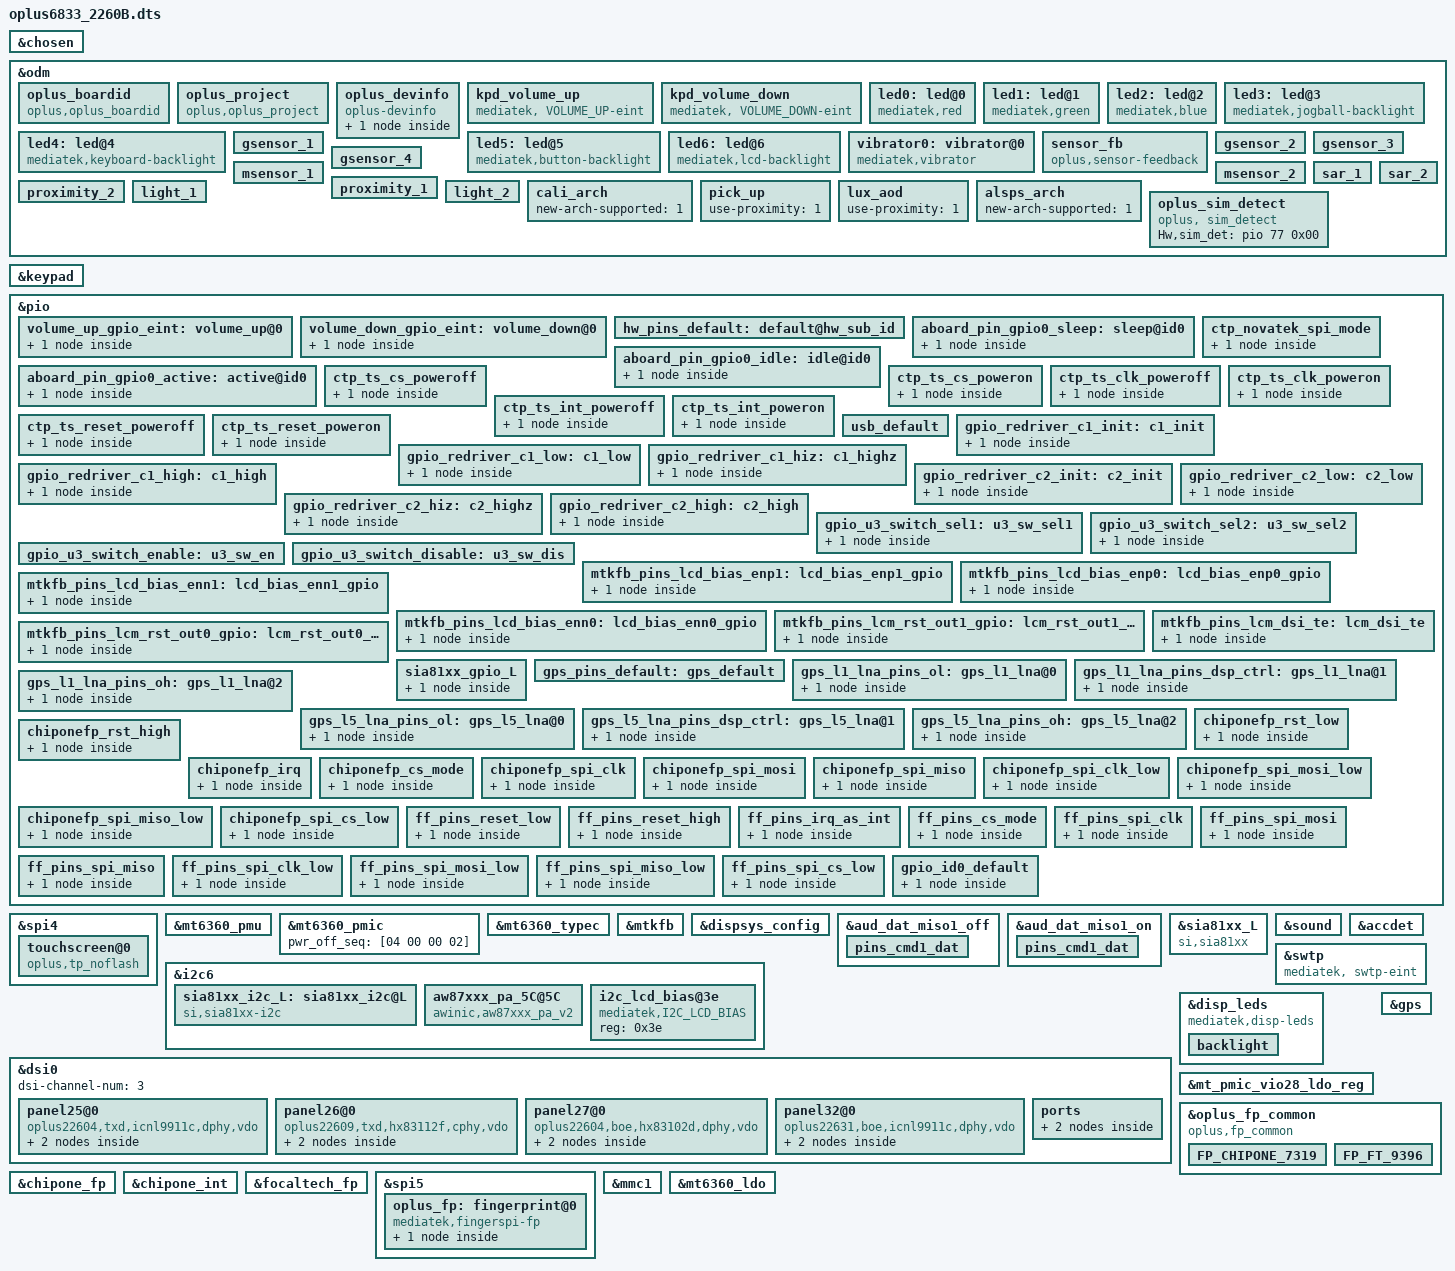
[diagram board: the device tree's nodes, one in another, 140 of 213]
// SPDX-License-Identifier: GPL-2.0
/*
 * Copyright (c) 2019 MediaTek Inc.
 *
 */
/dts-v1/;
/plugin/;
#include <dt-bindings/interrupt-controller/irq.h>
#include <dt-bindings/interrupt-controller/arm-gic.h>
#ifndef CONFIG_FPGA_EARLY_PORTING
#include <dt-bindings/pinctrl/mt6833-pinfunc.h>
#endif

/* chosen */
&chosen {
	atag,videolfb-fb_base_l = <0x7e605000>;
	atag,videolfb-fb_base_h = <0x0>;
	atag,videolfb-islcmfound = <1>;
	atag,videolfb-islcm_inited = <0>;
	atag,videolfb-fps= <6000>;
	atag,videolfb-vramSize= <0x1be0000>;
	atag,videolfb-lcmname=
		"nt35595_fhd_dsi_cmd_truly_nt50358_drv";
};

&odm {
	oplus_boardid:oplus_boardid {
		compatible = "oplus,oplus_boardid";
		oplus_boardid,dtsino="0x2260B";//only one u32
		oplus_boardid,pcbmask="0xffff";//all mask 0xffff
	};
	oplus_project:oplus_project {
		compatible = "oplus,oplus_project";
	};

	oplus_devinfo:oplus_devinfo {
		compatible = "oplus-devinfo";
		pinctrl-names = "default", "aboard_gpio0_sleep", "aboard_gpio0_active", "aboard_gpio0_idle";
		pinctrl-0 = <&hw_pins_default>;
		pinctrl-1 = <&aboard_pin_gpio0_sleep>;
		pinctrl-2 = <&aboard_pin_gpio0_active>;
		pinctrl-3 = <&aboard_pin_gpio0_idle>;
		main-sub {
			use_tristate_gpio;
			compatible = "hw-match, main-sub";
			aboard-gpio0 = <&pio 91 0x00>;
			aboard-patterns = <1>;	/*0[high-resistance] 1[pull-down] 2[pull-up]*/
			/*main board*/
			match-projects = <0x2260B>;
		};
	};

	kpd_volume_up:kpd_volume_up {
		compatible = "mediatek, VOLUME_UP-eint";
		interrupt-parent = <&pio>;
		interrupts = <1 IRQ_TYPE_EDGE_FALLING 1 0>;
		debounce = <32000>;
		status = "okay";
	};

	kpd_volume_down:kpd_volume_down {
		compatible = "mediatek, VOLUME_DOWN-eint";
		interrupt-parent = <&pio>;
		interrupts = <80 IRQ_TYPE_EDGE_FALLING 80 0>;
		debounce = <32000>;
		status = "okay";
	};
};
&keypad {
	keypad,volume-up	= <&pio 1 0x00>;
	keypad,volume-down	= <&pio 80 0x00>;
	pinctrl-names = "volume_up_as_int", "volume_down_as_int";
	pinctrl-0 = <&volume_up_gpio_eint>;
	pinctrl-1 = <&volume_down_gpio_eint>;
	status = "okay";
};
&pio {
	volume_up_gpio_eint:volume_up@0{
		pins_cmd_dat {
			pinmux = <PINMUX_GPIO1__FUNC_GPIO1>;
			slew-rate = <0>;  /*direction 0:in, 1:out*/
			input-enable;
		};
	};

	volume_down_gpio_eint:volume_down@0{
		pins_cmd_dat {
			pinmux = <PINMUX_GPIO80__FUNC_GPIO80>;
			slew-rate = <0>;  /*direction 0:in, 1:out*/
			input-enable;
		};
	};

	hw_pins_default:default@hw_sub_id {
	};
	aboard_pin_gpio0_sleep:sleep@id0 {
		pins_cmd_dat {
			pinmux = <PINMUX_GPIO91__FUNC_GPIO91>;
			slew-rate = <0>;
			bias-pull-down;
			input-enable;
		};
	};

	aboard_pin_gpio0_active:active@id0 {
		pins_cmd_dat {
			pinmux = <PINMUX_GPIO91__FUNC_GPIO91>;
			slew-rate = <0>;
			bias-pull-up;
			input-enable;
		};
	};

	aboard_pin_gpio0_idle:idle@id0 {
		pins_cmd_dat {
			pinmux = <PINMUX_GPIO91__FUNC_GPIO91>;
			slew-rate = <0>;
			bias-disable;
			input-enable;
		};
	};
};

&spi4 {
	status = "okay";
	#address-cells = <1>;
	#size-cells = <0>;

	touchscreen@0 {
		compatible = "oplus,tp_noflash";
		reg = <0>;
		chip-name = "himax,hx83112f_nf";
		status = "okay";

		spi-max-frequency = <9600000>;	//4800000,9600000,15000000,19200000
		interrupt-parent = <&pio>;
		interrupts = <14 IRQ_TYPE_EDGE_FALLING 14 0>;
		irq-gpio = <&pio 14 0x2002>;
		reset-gpio = <&pio 15 0>;

		/*driver match info*/
		tp_type = <21>; /*type:21 txd*/
		firmware_name = "0xAA270BI01";
		platform_support_project = <22609 22669 0x2260B 0x2266A 0x2266B 0x2266C>;
		platform_support_project_dir = <22609 22669 0x2260B 0x2266A 0x2266B 0x2266C>;
		platform_support_project_commandline = "default_commandline", "default_commandline", "default_commandline", "default_commandline", "default_commandline", "default_commandline";

		/*panel properities*/
		touchpanel,max-num-support = <10>;
		touchpanel,tx-rx-num = <16 36>;
		touchpanel,panel-coords = <1080 2408>;
		touchpanel,display-coords = <1080 2408>;
		touchpanel,touchmajor-limit = <0 216>;

		/*tp-pinctrl*/
		pinctrl-names = "default", "pin_set_low", "pin_set_high";
		pinctrl-0 = <&ctp_ts_int_poweron &ctp_ts_reset_poweron &ctp_novatek_spi_mode>;
		pinctrl-1 = <&ctp_ts_int_poweroff &ctp_ts_reset_poweroff &ctp_ts_cs_poweroff &ctp_ts_clk_poweroff>;
		pinctrl-2 = <&ctp_ts_int_poweron &ctp_ts_reset_poweron &ctp_ts_cs_poweron &ctp_ts_clk_poweron>;

		/*sw-feature*/
		incell_screen;
		irq_need_dev_resume_ok;
		fw_edge_limit_support;
		black_gesture_support;
		charger_pump_support;
		headset_pump_support;
		esd_handle_support;
		black_gesture_test_support;
		game_switch_support;
		noflash_support;
		lcd_trigger_load_tp_fw_support;
		smart_gesture_support;
		pressure_report_support;
		fw_update_app_support;
		health_monitor_v2_support;
		fw_update_in_probe_with_headfile;

		touchpanel,button-type = <4>;
	};

};

&pio {
	ctp_novatek_spi_mode:ctp_novatek_spi_mode{
		pins_cmd_dat {
			pinmux = <PINMUX_GPIO12__FUNC_SPI4_MI>,
				<PINMUX_GPIO13__FUNC_SPI4_MO>,
				<PINMUX_GPIO97__FUNC_SPI4_CLK>,
				<PINMUX_GPIO98__FUNC_SPI4_CSB>;
			drive-strength = <4>;
		};
	};
	ctp_ts_cs_poweroff: ctp_ts_cs_poweroff {
		pins_cmd_dat {
			pinmux = <PINMUX_GPIO98__FUNC_GPIO98>;
			slew-rate = <1>;
			output-low;
			bias-disable;
			//drive-strength = <4>;
		};
	};
	ctp_ts_cs_poweron: ctp_ts_cs_poweron {
		pins_cmd_dat {
			pinmux = <PINMUX_GPIO98__FUNC_SPI4_CSB>;
			drive-strength = <4>;
			//output-high;
		};
	};
	ctp_ts_clk_poweroff: ctp_ts_clk_poweroff {
		pins_cmd_dat {
			pinmux = <PINMUX_GPIO97__FUNC_GPIO97>;
			slew-rate = <1>;
			output-low;
			bias-disable;
			//drive-strength = <4>;
		};
	};
	ctp_ts_clk_poweron: ctp_ts_clk_poweron {
		pins_cmd_dat {
			pinmux = <PINMUX_GPIO97__FUNC_SPI4_CLK>;
			drive-strength = <4>;
			//output-high;
		};
	};
	ctp_ts_int_poweroff: ctp_ts_int_poweroff {
		pins_cmd_dat {
			pinmux = <PINMUX_GPIO14__FUNC_GPIO14>;
			slew-rate = <1>;
			output-low;
			bias-disable;
		};
	};
	ctp_ts_int_poweron: ctp_ts_int_poweron {
		pins_cmd_dat {
			pinmux = <PINMUX_GPIO14__FUNC_GPIO14>;
			slew-rate = <0>;
			input-enable;
			bias-pull-up = <00>;
		};
	};
	ctp_ts_reset_poweroff: ctp_ts_reset_poweroff {
		pins_cmd_dat {
			pinmux = <PINMUX_GPIO15__FUNC_GPIO15>;
			slew-rate = <1>;
			output-low;
			bias-disable;
		};
	};

	ctp_ts_reset_poweron: ctp_ts_reset_poweron {
		pins_cmd_dat {
			pinmux = <PINMUX_GPIO15__FUNC_GPIO15>;
			slew-rate = <1>;
			output-high;
			bias-disable;
		};
	};
};

/* USB SWITCH GPIO start */
&pio {
	usb_default: usb_default {
	};

	gpio_redriver_c1_init: c1_init {
		pins_cmd_dat {
			pinmux = <PINMUX_GPIO41__FUNC_GPIO41>;
			slew-rate = <1>;
			output-low;
		};
	};

	gpio_redriver_c1_low: c1_low {
		pins_cmd_dat {
			pinmux = <PINMUX_GPIO41__FUNC_GPIO41>;
			slew-rate = <1>;
			output-low;
		};
	};

	gpio_redriver_c1_hiz: c1_highz {
		pins_cmd_dat {
			pinmux = <PINMUX_GPIO41__FUNC_GPIO41>;
			slew-rate= <0>;
			bias-disable;
		};
	};

	gpio_redriver_c1_high: c1_high {
		pins_cmd_dat {
			pinmux = <PINMUX_GPIO41__FUNC_GPIO41>;
			slew-rate = <1>;
			output-high;
		};
	};

	gpio_redriver_c2_init: c2_init {
		pins_cmd_dat {
			pinmux = <PINMUX_GPIO40__FUNC_GPIO40>;
			slew-rate = <1>;
			output-low;
		};
	};

	gpio_redriver_c2_low: c2_low {
		pins_cmd_dat {
			pinmux = <PINMUX_GPIO40__FUNC_GPIO40>;
			slew-rate = <1>;
			output-low;
		};
	};

	gpio_redriver_c2_hiz: c2_highz {
		pins_cmd_dat {
			pinmux = <PINMUX_GPIO40__FUNC_GPIO40>;
			slew-rate= <0>;
			bias-disable;
		};
	};

	gpio_redriver_c2_high: c2_high {
		pins_cmd_dat {
			pinmux = <PINMUX_GPIO40__FUNC_GPIO40>;
			slew-rate = <1>;
			output-high;
		};
	};

	gpio_u3_switch_sel1: u3_sw_sel1 {
		pins_cmd_dat {
			pinmux = <PINMUX_GPIO11__FUNC_GPIO11>;
			slew-rate = <1>;
			output-low;
		};
	};

	gpio_u3_switch_sel2: u3_sw_sel2 {
		pins_cmd_dat {
			pinmux = <PINMUX_GPIO11__FUNC_GPIO11>;
			slew-rate = <1>;
			output-high;
		};
	};

	gpio_u3_switch_enable: u3_sw_en {
	};

	gpio_u3_switch_disable: u3_sw_dis {
	};
};

&mt6360_pmu {
	mt6360,intr_gpio_num = <10>; /* direct defined GPIO num */
	mt6360,intr_gpio = <&pio 10 0x0>;
};

&mt6360_pmic {
	pwr_off_seq = [04 00 00 02];
};

&mt6360_typec {
	mt6360pd,intr_gpio_num = <11>; /* direct defined GPIO num */
	mt6360pd,intr_gpio = <&pio 11 0x0>;
};

#ifndef CONFIG_FPGA_EARLY_PORTING
&pio {
	mtkfb_pins_lcd_bias_enp1: lcd_bias_enp1_gpio {
		pins_cmd_dat {
			pinmux = <PINMUX_GPIO137__FUNC_GPIO137>;
			slew-rate = <1>;
			output-high;
		};
	};

	mtkfb_pins_lcd_bias_enp0: lcd_bias_enp0_gpio {
		pins_cmd_dat {
			pinmux = <PINMUX_GPIO137__FUNC_GPIO137>;
			slew-rate = <1>;
			output-low;
		};
	};

	mtkfb_pins_lcd_bias_enn1: lcd_bias_enn1_gpio {
		pins_cmd_dat {
			pinmux = <PINMUX_GPIO138__FUNC_GPIO138>;
			slew-rate = <1>;
			output-high;
		};
	};

	mtkfb_pins_lcd_bias_enn0: lcd_bias_enn0_gpio {
		pins_cmd_dat {
			pinmux = <PINMUX_GPIO138__FUNC_GPIO138>;
			slew-rate = <1>;
			output-low;
		};
	};

	mtkfb_pins_lcm_rst_out1_gpio: lcm_rst_out1_gpio {
		pins_cmd_dat {
			pinmux = <PINMUX_GPIO86__FUNC_GPIO86>;
			slew-rate = <1>;
			output-high;
		};
	};

	mtkfb_pins_lcm_rst_out0_gpio: lcm_rst_out0_gpio {
		pins_cmd_dat {
			pinmux = <PINMUX_GPIO86__FUNC_GPIO86>;
			slew-rate = <1>;
			output-low;
		};
	};
	mtkfb_pins_lcm_dsi_te: lcm_dsi_te {
		pins_cmd_dat {
			pinmux = <PINMUX_GPIO84__FUNC_DSI_TE>;
		};
	};
};

&mtkfb {
	pinctrl-names = "lcd_bias_enp1_gpio", "lcd_bias_enp0_gpio",
		"lcd_bias_enn1_gpio", "lcd_bias_enn0_gpio",
		"lcm_rst_out1_gpio", "lcm_rst_out0_gpio",
		"mode_te_te";
	pinctrl-0 = <&mtkfb_pins_lcd_bias_enp1>;
	pinctrl-1 = <&mtkfb_pins_lcd_bias_enp0>;
	pinctrl-2 = <&mtkfb_pins_lcd_bias_enn1>;
	pinctrl-3 = <&mtkfb_pins_lcd_bias_enn0>;
	pinctrl-4 = <&mtkfb_pins_lcm_rst_out1_gpio>;
	pinctrl-5 = <&mtkfb_pins_lcm_rst_out0_gpio>;
	pinctrl-6 = <&mtkfb_pins_lcm_dsi_te>;
	status = "okay";
};
&dispsys_config {
	pinctrl-names =
		"lcm_rst_out1_gpio", "lcm_rst_out0_gpio",
		"mode_te_te";
	pinctrl-0 = <&mtkfb_pins_lcm_rst_out1_gpio>;
	pinctrl-1 = <&mtkfb_pins_lcm_rst_out0_gpio>;
	pinctrl-2 = <&mtkfb_pins_lcm_dsi_te>;
	status = "okay";

	helper-value = <0>, /*MTK_DRM_OPT_STAGE*/
		<1>, /*MTK_DRM_OPT_USE_CMDQ*/
		<1>, /*MTK_DRM_OPT_USE_M4U*/
		<0>, /*MTK_DRM_OPT_SODI_SUPPORT*/
		<1>, /*MTK_DRM_OPT_IDLE_MGR*/
		<0>, /*MTK_DRM_OPT_IDLEMGR_SWTCH_DECOUPLE*/
		<0>, /*MTK_DRM_OPT_IDLEMGR_BY_REPAINT*/
		<0>, /*MTK_DRM_OPT_IDLEMGR_ENTER_ULPS*/
		<0>, /*MTK_DRM_OPT_IDLEMGR_KEEP_LP11*/
		<0>, /*MTK_DRM_OPT_DYNAMIC_RDMA_GOLDEN_SETTING*/
		<1>, /*MTK_DRM_OPT_IDLEMGR_DISABLE_ROUTINE_IRQ*/
		<0>, /*MTK_DRM_OPT_MET_LOG*/
		<1>, /*MTK_DRM_OPT_USE_PQ*/
		<1>, /*MTK_DRM_OPT_ESD_CHECK_RECOVERY*/
		<0>, /*MTK_DRM_OPT_ESD_CHECK_SWITCH*/
		<1>, /*MTK_DRM_OPT_PRESENT_FENCE*/
		<0>, /*MTK_DRM_OPT_RDMA_UNDERFLOW_AEE*/
		<1>, /*MTK_DRM_OPT_DSI_UNDERRUN_AEE*/
		<1>, /*MTK_DRM_OPT_HRT*/
		<1>, /*MTK_DRM_OPT_HRT_MODE*/
		<0>, /*MTK_DRM_OPT_DELAYED_TRIGGER*/
		<1>, /*MTK_DRM_OPT_OVL_EXT_LAYER*/
		<0>, /*MTK_DRM_OPT_AOD*/
		<1>, /*MTK_DRM_OPT_RPO*/
		<0>, /*MTK_DRM_OPT_DUAL_PIPE*/
		<0>, /*MTK_DRM_OPT_DC_BY_HRT*/
		<0>, /*MTK_DRM_OPT_OVL_WCG*/
		<0>, /*MTK_DRM_OPT_OVL_SBCH*/
		<1>, /*MTK_DRM_OPT_COMMIT_NO_WAIT_VBLANK*/
		<0>, /*MTK_DRM_OPT_MET*/
		<0>, /*MTK_DRM_OPT_REG_PARSER_RAW_DUMP*/
		<0>, /*MTK_DRM_OPT_VP_PQ*/
		<0>, /*MTK_DRM_OPT_GAME_PQ*/
		<0>, /*MTK_DRM_OPT_MMPATH*/
		<0>, /*MTK_DRM_OPT_HBM*/
		<1>, /*MTK_DRM_OPT_VDS_PATH_SWITCH*/
		<0>, /*MTK_DRM_OPT_LAYER_REC*/
		<1>; /*MTK_DRM_OPT_CLEAR_LAYER*/
};

/* add for dual-mic or singlemic with miso1 */
&aud_dat_miso1_off {
	pins_cmd1_dat {
		pinmux = <PINMUX_GPIO160__FUNC_GPIO160>;
		input-enable;
		bias-pull-down;
	};
};
&aud_dat_miso1_on {
	pins_cmd1_dat {
		pinmux = <PINMUX_GPIO160__FUNC_AUD_DAT_MISO1>;
		input-schmitt-enable;
		bias-disable;
	};
};

&pio {
	sia81xx_gpio_L: sia81xx_gpio_L {
		pins_cmd_dat {
			pinmux = <PINMUX_GPIO94__FUNC_GPIO94>;
			slew-rate = <1>;
			bias-disable;
		};
	};
};

&sia81xx_L {
	compatible = "si,sia81xx";
	si,sia81xx_type = "sia8100";
	si,sia81xx_reset = <&pio 94 0>;
	si,sia81xx_owi = <&pio 94 0>;
	si,sia_boost_vol_support = <1>;
	pinctrl-names = "sia81xx_gpio";
	pinctrl-0 = <&sia81xx_gpio_L>;
	si,sia81xx_disable_pin = <0>;
	/* the same value share a same task
	 * valid value range : 0 ~ 7 */
	timer_task_hdl = <0>;
	channel_num = <0>;
	owi_mode = <2>;
	en_x_filter = <0>;
	en_dynamic_updata_vdd = <1>;
	dynamic_updata_vdd_port = <0x8>;
	algo_is_v2 = <1>;
};

&sound {
	/* this dtsi config for product's special config, AudioHal read ctl 'OPLUS_AUDIO_EXTEN_CONFIG' get the values*
	 * 1st value --> PA type: 0:NXP Pa, 1:Awinic Pa 2:sia81xx Pa*/
	audio_extern_config = <2>;
	si,sia81xx-max-num = <1>;
	si,sia81xx-aux-devs = <&sia81xx_L>;
	si,sia81xx-aux-devs-prefix = "SpkrLeft";
};

&i2c6 {
        sia81xx_i2c_L: sia81xx_i2c@L {
                compatible = "si,sia81xx-i2c";
                reg = <0x28>;
                si,sia81xx-dev = <&sia81xx_L>;
        };

	aw87xxx_pa_5C@5C {
		compatible = "awinic,aw87xxx_pa_v2";
		reset-gpio = <&pio 94 0>;
		reg = <0x5C>;
		dev_index = < 0 >;
		status = "okay";
	};

       i2c_lcd_bias@3e {
               compatible = "mediatek,I2C_LCD_BIAS";
               reg = <0x3e>;
               status = "okay";
       };
};

&dsi0 {
	status = "okay";
	dsi-channel-num = <3>;
	#address-cells = <1>;
	#size-cells = <0>;
	panel25@0 {
		compatible = "oplus22604,txd,icnl9911c,dphy,vdo";
		reg = <0>;
		reset-gpios = <&pio 86 0>;
		ldo-gpios = <&pio 41 0>;
		bias-gpios = <&pio 138 0>,
				<&pio 137 0>;
		pinctrl-names = "default";
		port {
			panel_in25: endpoint {
				remote-endpoint = <&dsi_out>;
			};
		};
	};
	panel26@0 {
		compatible = "oplus22609,txd,hx83112f,cphy,vdo";
		reg = <1>;
		reset-gpios = <&pio 86 0>;
		ldo-gpios = <&pio 41 0>;
		bias-gpios = <&pio 138 0>,
				<&pio 137 0>;
		pinctrl-names = "default";
		port {
			panel_in26: endpoint {
				remote-endpoint = <&dsi_out>;
			};
		};
	};
	panel27@0 {
		compatible = "oplus22604,boe,hx83102d,dphy,vdo";
		reg = <2>;
		reset-gpios = <&pio 86 0>;
		ldo-gpios = <&pio 41 0>;
		bias-gpios = <&pio 138 0>,
				<&pio 137 0>;
		pinctrl-names = "default";
		port {
			panel_in27: endpoint {
				remote-endpoint = <&dsi_out>;
			};
		};
	};
	panel32@0 {
		compatible = "oplus22631,boe,icnl9911c,dphy,vdo";
		reg = <3>;
		reset-gpios = <&pio 86 0>;
		ldo-gpios = <&pio 41 0>;
		bias-gpios = <&pio 138 0>,
				<&pio 137 0>;
		pinctrl-names = "default";
		port {
			panel_in32: endpoint {
				remote-endpoint = <&dsi_out>;
			};
		};
	};
	ports {
		port {
			dsi_out: endpoint {
				remote-endpoint = <&panel_in25>;
			};
		};
	};
};
#endif

/* delete default keys pinctrl
&keypad {
	pinctrl-names = "default";
	pinctrl-0 = <&kpd_pins_default>;
};

&pio {
	kpd_pins_default: kpdgpiodefault {
		pins_cmd_dat {
			pinmux = <PINMUX_GPIO79__FUNC_KPCOL0>;
			bias-pull-up = <MTK_PUPD_SET_R1R0_10>;
			output-low;
			input-schmitt-enable;
		};
	};
};
*/

//#include "mediatek/cust_mt6833_touch_1080x2300.dtsi"
/* accdet start */
&accdet {
	/* accdet micbias voltage: 0x09:2.85v 0x08:2.8v 0x07,
	 * 2.7v;0x05,2.5v;0x02,1.9v
	 */
	accdet-mic-vol = <7>;
	/* accdet pwm_width, pwm_thresh, fall_delay, rise_delay
	 * debounce0, debounce1, debounce3, debounce4
	 * eint pwm_width, eint pwm_thresh
	 * eint deb(debounce0, debounce1, debounce2, debounce3), inv_debounce
	 */

	headset-mode-setting = <0x500 0x500 1 0x1f0
				0x1325 0x800 0x3D4 0x44
				0x0 0x7
				0x5 0x9 0x9 0xd 0xe>;
	/*headset-mode-setting = <0x500 0x500 1 0x1f0
	*                      0x800 0x800 0x20 0x44
	*                      0x4 0x1
	*                      0x5 0x3 0x3 0x5 0xe>;
	*/

	accdet-plugout-debounce = <1>;
	/*1:ACC mode, 2:low cost without in bias, 6:low cost with in bias*/
	accdet-mic-mode = <2>;
	/*0--MD_MAX--UP_MAX--DW_MAX*/
	headset-three-key-threshold = <0 82 170 306>;
	//headset-three-key-threshold = <0 80 220 400>;
	headset-three-key-threshold-CDD = <0 121 192 600>;
	/*0--MD_MAX--VOICE_MAX--UP_MAX--DW_MAX*/
	headset-four-key-threshold = <0 58 121 192 400>;
	/* moisture HW mode config start. Enable moisture detection or not
	 * default use HW mode for moisture detection
	 */
	moisture_detect_enable = <1>;
	/* select VTH to 2v and 500k, use internal resitance */
	eint_use_ext_res = <0>;
	/* enable eint detection mode, if moisture detection enable
	 * eint_detect_mode = moisture_detect_mode;otherwise, select
	 * eint_detect_mode = 4 as DEFAULT
	 */
	eint_detect_mode = <5>;
	/* enable moisture detection mode, if moisture detection enable
	 * eint_detect_mode = moisture_detect_mode
	 */
	moisture_detect_mode = <5>;
	/* select 0: 2.8V; 1: 2.4V; 2: 2V; 3: VTH=MVTH(VTH2) */
	moisture_comp_vth = <2>;
//#ifdef OPLUS_BUG_COMPATIBILITY
	moisture_comp_vref2 = <2>;
//#else
	/* vref2 voltage for different water impedance */
	//moisture_comp_vref2 = <0>;
//#endif
	/* moisture HW mode config end */

	/* moisture SW mode config start, use external resister or not.
	 * DEFAULT NOT NEED
	 */
	moisture_use_ext_res = <0>;
	/* moisture external resister ohm, SW mode by auxadc */
	moisture-external-r = <2000000>;
	/* moisture internal resister ohm, SW mode by auxadc */
	moisture-internal-r = <47000>;
	/* moisture of water resister ohm, SW mode by auxadc*/
	moisture-water-r = <10000>;
	/* moisture SW mode config end */
        //#endif /* VENDOR_EDIT */
	status = "okay";
};
/* accdet end */

//#ifdef OPLUS_FEATURE_SWTP
&swtp {
    compatible = "mediatek, swtp-eint";
};
//#endif  /*OPLUS_FEATURE_SWTP*/

&disp_leds {
	compatible = "mediatek,disp-leds";
        backlight {
                label = "lcd-backlight";
                max-brightness = <4095>;
                led-bits = <12>;
                trans-bits = <12>;
                default-state = "on";
        };
};

&mt_pmic_vio28_ldo_reg {
	regulator-name = "vio28";
	regulator-min-microvolt = <3000000>;
	regulator-max-microvolt = <3000000>;
	regulator-enable-ramp-delay = <1920>;
};

&odm {
	led0:led@0 {
		compatible = "mediatek,red";
		led_mode = <0>;
		data = <1>;
		pwm_config = <0 0 0 0 0>;
	};
	led1:led@1 {
		compatible = "mediatek,green";
		led_mode = <0>;
		data = <1>;
		pwm_config = <0 0 0 0 0>;
	};
	led2:led@2 {
		compatible = "mediatek,blue";
		led_mode = <0>;
		data = <1>;
		pwm_config = <0 0 0 0 0>;
	};
	led3:led@3 {
		compatible = "mediatek,jogball-backlight";
		led_mode = <0>;
		data = <1>;
		pwm_config = <0 0 0 0 0>;
	};
	led4:led@4 {
		compatible = "mediatek,keyboard-backlight";
		led_mode = <0>;
		data = <1>;
		pwm_config = <0 0 0 0 0>;
	};
	led5:led@5 {
		compatible = "mediatek,button-backlight";
		led_mode = <0>;
		data = <1>;
		pwm_config = <0 0 0 0 0>;
	};
	led6:led@6 {
		compatible = "mediatek,lcd-backlight";
		led_mode = <4>;
		data = <1>;
		pwm_config = <0 1 0 0 0>;
	};
	vibrator0:vibrator@0 {
		compatible = "mediatek,vibrator";
	};
	sensor_fb: sensor_fb {
		compatible = "oplus,sensor-feedback";
	};

	/*
	enum {
		LIS3DH,
		LSM6DS3,
		BMI160,
		LIS2HH12,
		LSM6DSM,
		BMI2XY,
		LSM6DSO,
		ICM4X6XX,
		SC7A20,
		BMA4XY,
		BMI3XY,
		ICM4N607,
		BMA2X2,
		MC34X9,
		STK8XXX,
	};
	*/

	gsensor_1: gsensor_1 {
		status = "okay";
		sensor_name = <8>;//SC7A20
		device_name = "sc7a20";
		i2c_num = <2>;
		i2c_addr = <0>;
		direction = <2>;
		eint_num = <3>;
		gyro_cali_version= <2>;
		acc_cali_range= <300 300 300>; //300mg
		device_id = <1>; //0 sc7a20,1 sc7a20e
	};
	gsensor_2: gsensor_2 {
		status = "okay";
		sensor_name = <12>;//BMA2X2
		device_name = "bma2x2";
		i2c_num = <2>;
		i2c_addr = <0>;
		direction = <3>;
		eint_num = <3>;
		gyro_cali_version= <2>;
		acc_cali_range= <300 300 300>; //300mg
	};
	gsensor_3: gsensor_3 {
		status = "okay";
		sensor_name = <13>;//MC34X9
		device_name = "mc34x9";
		i2c_num = <2>;
		i2c_addr = <0>;
		direction = <3>;
		eint_num = <3>;
		gyro_cali_version= <2>;
		acc_cali_range= <300 300 300>; //300mg
		device_id = <1>; //0 sc7a20,1 sc7a20e
	};
	gsensor_4: gsensor_4 {
		status = "okay";
		sensor_name = <14>;//STK8XXX
		device_name = "stk8xxx";
		i2c_num = <2>;
		i2c_addr = <0>;
		direction = <3>;
		eint_num = <3>;
		gyro_cali_version= <2>;
		acc_cali_range= <300 300 300>; //300mg
	};
	/*
	enum {
		AKM09911,
		MMC3530,
		MMC5603,
		MXG4300,
		QMC6308,
	};
	*/
	msensor_1: msensor_1 {
		status = "okay";
		sensor_name = <2>;//MMC5603
		i2c_num = <0>;
		i2c_addr = <48>;
		direction = <0>;
		eint_num = <0>;
		soft-mag-parameter = <9966 0 152 0 15 0 26 1 10224 0 285 1 795 1 182 0 11638 0>;
	};
	msensor_2: msensor_2 {
		status = "okay";
		sensor_name = <4>;//QMC6308
		i2c_num = <0>;
		i2c_addr = <44>;
		direction = <0>;
		eint_num = <0>;
		soft-mag-parameter = <10000 0 0 0 0 0 0 0 10000 0 0 0 0 0 0 0 10000 0>;
	};
	/*
	enum {
		SX933x,
		SX933xs,
		AW9610X,
	};
	*/
	sar_1: sar_1 {
		status = "okay";
		sensor_name = <2>;//AW9610X
		i2c_num = <0>;
		i2c_addr = <0x12>;
		direction = <0>;
		eint_num = <11>;
		channel_num = <3>;
		channel_0_min = <0>;
		channel_0_max = <70000>;
		channel_1_min = <0>;
		channel_1_max = <70000>;
		channel_2_min = <0>;
		channel_2_max = <70000>;
		channel_3_min = <0>;
		channel_3_max = <70000>;
		reg_table_num = <0>;
	};
	sar_2: sar_2 {
		status = "okay";
		sensor_name = <0>;//SX933x
		i2c_num = <0>;
		i2c_addr = <0x28>;
		direction = <0>;
		eint_num = <11>;
		channel_num = <3>;
		channel_0_min = <0>;
		channel_0_max = <70000>;
		channel_1_min = <0>;
		channel_1_max = <70000>;
		channel_2_min = <0>;
		channel_2_max = <70000>;
		channel_3_min = <0>;
		channel_3_max = <70000>;
		reg_table_num = <7>;
	};
	/*
	enum {
		TMD2725,
		APSD9922,
		STK3335,
		STK3331,
		STK2232,
		TCS3701,
		STK32600,
		STK33502,
		MN78911,
		TMD2755x12,
	};
	*/
	proximity_1: proximity_1 {
		status = "okay";
		sensor_name = <7>;//STK33502
		i2c_num = <0>;
		i2c_addr = <0x46>;
		direction = <4>;
		eint_num = <3>;
		low_step = <300>;
		high_step = <400>;
		low_limit = <650>;
		high_limit = <1050>;
		dirty_low_step = <200>;
		dirty_high_step = <300>;
		ps_dirty_limit = <2000>;
		ps_ir_limit = <2000>;
		ps_adjust_min = <0>;
		ps_adjust_max = <1850>;
		sampling_count = <5>;
		step_max = <400>;
		step_min = <100>;
		step_div = <2000>;
		anti_shake_delta = <70>;
		dynamic_cali_max = <5000>;
		raw2offset_radio = <1000>;
		offset_max = <60000>;
		offset_range_min = <0>;
		offset_range_max = <65534>;
		force_cali_limit = <2000>;
		cali_jitter_limit = <30>;
		cal_offset_margin = <3000>;
		sensor-reg = <0x01 0x33>;
	};
	proximity_2: proximity_2 {
		status = "okay";
		sensor_name = <9>;//TMD2755x12
		i2c_num = <0>;
		i2c_addr = <0x39>;
		direction = <4>;
		eint_num = <2>;
		low_step = <200>;
		high_step = <300>;
		low_limit = <400>;
		high_limit = <600>;
		dirty_low_step = <400>;
		dirty_high_step = <600>;
		ps_dirty_limit = <1023>;
		ps_ir_limit = <500>;
		ps_adjust_min = <0>;
		ps_adjust_max = <600>;
		sampling_count = <5>;
		step_max = <400>;
		step_min = <100>;
		step_div = <1500>;
		anti_shake_delta = <100>;
		dynamic_cali_max = <1024>;
		raw2offset_radio = <24000>;
		offset_max = <250>;
		offset_range_min = <255>;
		offset_range_max = <255>;
		force_cali_limit = <2000>;
		cali_jitter_limit = <30>;
		cal_offset_margin = <120>;
		is_use_force_cali = <1>;
		ps_int_enable = <0>;
	};
	light_1: light_1 {
		status = "okay";
		sensor_name = <7>;//STK33502
		i2c_num = <0>;
		i2c_addr = <0x46>;
		direction = <4>;
		eint_num = <3>;
		als_buffer_length =<8>;
		als_ratio = <90>;
		als_type = <1>;//<1-normal;2-under screen;3-normal needed compensation>
		device_name = "stk33502";
		als_spectral_coefficient = <1>;
		coefficient_mode = <6>; //6x coefficient mode
		als_coef_a = <8500>; //*100
		als_coef_b = <39500>; //*100
		als_coef_c = <4300>; //*100
		als_coef_d = <14300>; //*100
		als_coef_e = <10000>; //*100
		als_coef_ratio = <70>;
	};
	light_2: light_2 {
		status = "okay";
		sensor_name = <9>;//TMD2755x12
		i2c_num = <0>;
		i2c_addr = <0x39>;
		direction = <4>;
		eint_num = <2>;
		als_buffer_length =<8>;
		als_ratio = <90>;
		als_type = <1>;//<1-normal;2-under screen;3-normal needed compensation>
		device_name = "tmd2755x12";
		als_spectral_coefficient = <0x08>;
		als_coef_a = <3575>;
		als_coef_b = <1291>;
		als_coef_c = <1548>;
		als_coef_d = <141>; //*1000
		als_coef_e = <100>; //*1000
		als_coef_ratio = <602>; //*1000
		offset_gain = <200>; //*1000
		scale_gain = <600>; //*1000
		lux_revocer = <1000>; //*1000
		esd_gpio_offset = <0x150>;
		esd_gpio_bit = <17>;
		esd_gpio_use = <1>; //default must 0
	};
	cali_arch: cali_arch {
		status = "okay";
		new-arch-supported = <1>;
	};
	pick_up: pick_up {
		status = "okay";
		use-proximity = <1>;
	};
	lux_aod: lux_aod {
		status = "okay";
		use-proximity = <1>;
	};
	alsps_arch: alsps_arch {
		status = "okay";
		new-arch-supported = <1>;
	};
    oplus_sim_detect {
        compatible = "oplus, sim_detect";
        Hw,sim_det = <&pio 77 0x00>;
    };
};

/* GPS GPIO standardization start */
&pio {
	gps_pins_default: gps_default {
	};

	gps_l1_lna_pins_ol: gps_l1_lna@0 {
		pins_cmd_dat {
			pinmux = <PINMUX_GPIO87__FUNC_GPIO87>;
			output-low;
		};
	};
	gps_l1_lna_pins_dsp_ctrl: gps_l1_lna@1 {
		pins_cmd_dat {
			pinmux = <PINMUX_GPIO87__FUNC_GPS_L1_ELNA_EN>;
		};
	};
	gps_l1_lna_pins_oh: gps_l1_lna@2 {
		pins_cmd_dat {
			pinmux = <PINMUX_GPIO87__FUNC_GPIO87>;
			output-high;
		};
	};

	gps_l5_lna_pins_ol: gps_l5_lna@0 {
		pins_cmd_dat {
			pinmux = <PINMUX_GPIO91__FUNC_GPIO91>;
			output-low;
		};
	};
	gps_l5_lna_pins_dsp_ctrl: gps_l5_lna@1 {
		pins_cmd_dat {
			pinmux = <PINMUX_GPIO91__FUNC_GPS_L5_ELNA_EN>;
		};
	};
	gps_l5_lna_pins_oh: gps_l5_lna@2 {
		pins_cmd_dat {
			pinmux = <PINMUX_GPIO91__FUNC_GPIO91>;
			output-high;
		};
	};
};

&gps {
	pinctrl-names = "default",
		"gps_l1_lna_disable",
		"gps_l1_lna_dsp_ctrl",
		"gps_l1_lna_enable",
		"gps_l5_lna_disable",
		"gps_l5_lna_dsp_ctrl",
		"gps_l5_lna_enable";
	pinctrl-0 = <&gps_pins_default>;
	pinctrl-1 = <&gps_l1_lna_pins_ol>;
	pinctrl-2 = <&gps_l1_lna_pins_dsp_ctrl>;
	pinctrl-3 = <&gps_l1_lna_pins_oh>;
	pinctrl-4 = <&gps_l5_lna_pins_ol>;
	pinctrl-5 = <&gps_l5_lna_pins_dsp_ctrl>;
	pinctrl-6 = <&gps_l5_lna_pins_oh>;
	status = "okay";
};

//#ifdef OPLUS_FEATURE_FINGERPRINT
&oplus_fp_common {
	compatible = "oplus,fp_common"; //Manufacture, and Model
	oplus,fp_gpio_num = <1>;
	oplus,fp_gpio_0 = <&pio 180 0x00>;
	FP_CHIPONE_7319 {
		oplus,fp-id = <0>; /* fp id mapping table */
		vendor-chip = <24>; /* please refer to the struct fp_vendor_t in oplus_fp_commmon.n */
		eng-menu = "-1,-1"; /* represents SNR, inclination test item in engineer menu, and 0/1 means off/on */
		chip-name = "C_7319";  /* /proc/fp_id, will be displayed in engineer menu  */
	};
	FP_FT_9396{
		oplus,fp-id = <1>; /* fp id mapping table */
		vendor-chip = <33>; /* please refer to the struct fp_vendor_t in oplus_fp_commmon.h */
		eng-menu = "-1,-1"; /* represents SNR, inclination test item in engineer menu, and 0/1 means off/on */
		chip-name = "F_9396";  /* /proc/fp_id, will be displayed in engineer menu  */
	};
};

&chipone_fp {
    interrupt-parent = <&pio>;
    interrupts = <22 IRQ_TYPE_EDGE_RISING 22 0>;
	pinctrl-names = "fpsensor_finger_rst_low", "fpsensor_finger_rst_high", "irq-init", "fpsensor_finger_cs_mode",
                    "fpsensor_finger_clk", "fpsensor_finger_mosi", "fpsensor_finger_miso",
                    "fpsensor_finger_clk_low", "fpsensor_finger_mosi_low", "fpsensor_finger_miso_low", "fpsensor_finger_cs_low";
	pinctrl-0 = <&chiponefp_rst_low>;
	pinctrl-1 = <&chiponefp_rst_high>;
	pinctrl-2 = <&chiponefp_irq>;
	pinctrl-3 = <&chiponefp_cs_mode>;
	pinctrl-4 = <&chiponefp_spi_clk>;
	pinctrl-5 = <&chiponefp_spi_mosi>;
	pinctrl-6 = <&chiponefp_spi_miso>;
	pinctrl-7 = <&chiponefp_spi_clk_low>;
	pinctrl-8 = <&chiponefp_spi_mosi_low>;
	pinctrl-9 = <&chiponefp_spi_miso_low>;
	pinctrl-10 = <&chiponefp_spi_cs_low>;
	status = "okay";
};

&chipone_int {
    interrupt-parent = <&pio>;
    interrupts = <22 IRQ_TYPE_EDGE_RISING 22 0>;
        pinctrl-names = "irq-init";
        pinctrl-0 = <&chiponefp_irq>;
        status = "okay";
};

&pio {
        chiponefp_rst_low: chiponefp_rst_low {
                pins_cmd_dat {
                        pinmux = <PINMUX_GPIO21__FUNC_GPIO21>;
                        slew-rate = <1>;
                        output-low;
                };
        };
        chiponefp_rst_high: chiponefp_rst_high {
                pins_cmd_dat {
                        pinmux = <PINMUX_GPIO21__FUNC_GPIO21>;
                        slew-rate = <1>;
                        output-high;
                };
        };
        chiponefp_irq: chiponefp_irq {
                pins_cmd_dat {
                        pinmux = <PINMUX_GPIO22__FUNC_GPIO22>;
                        slew-rate = <0>;
                        bias-disable;
                };
        };
	chiponefp_cs_mode: chiponefp_cs_mode {
		pins_cmd_dat {
			pinmux = <PINMUX_GPIO36__FUNC_SPI5_CSB>;
			drive-strength = <2>;
		};
	};
    chiponefp_spi_clk: chiponefp_spi_clk {
		pins_cmd_dat {
			pinmux = <PINMUX_GPIO35__FUNC_SPI5_CLK>;
			drive-strength = <2>;
		};
	};
    chiponefp_spi_mosi: chiponefp_spi_mosi {
		pins_cmd_dat {
			pinmux = <PINMUX_GPIO37__FUNC_SPI5_MO>;
			drive-strength = <2>;
		};
	};
    chiponefp_spi_miso: chiponefp_spi_miso {
		pins_cmd_dat {
			pinmux = <PINMUX_GPIO38__FUNC_SPI5_MI>;
			drive-strength = <3>;
		};
	};
    chiponefp_spi_clk_low: chiponefp_spi_clk_low {
		pins_cmd_dat {
			pinmux = <PINMUX_GPIO35__FUNC_GPIO35>;
			slew-rate = <1>;
			output-low;
		};
	};
    chiponefp_spi_mosi_low: chiponefp_spi_mosi_low {
		pins_cmd_dat {
			pinmux = <PINMUX_GPIO37__FUNC_GPIO37>;
			slew-rate = <1>;
			output-low;
        };
    };
    chiponefp_spi_miso_low: chiponefp_spi_miso_low {
		pins_cmd_dat {
			pinmux = <PINMUX_GPIO38__FUNC_SPI5_MI>;
			slew-rate = <1>;
			output-low;
		};
	};
    chiponefp_spi_cs_low: chiponefp_spi_cs_low {
		pins_cmd_dat {
			pinmux = <PINMUX_GPIO36__FUNC_GPIO36>;
			slew-rate = <1>;
			output-low;
		};
	};
};

&focaltech_fp {
	focaltech_fp,reset-gpio = <&pio 21 0>;
	focaltech_fp,irq-gpio = <&pio 22 0>;
	focaltech_fp,use-regulator;
	//focaltech_fp,use-pinctrl;
	focaltech_fp,spiclk;
	ff_vdd-supply = <&mt_pmic_vfp_ldo_reg>;
	pinctrl-names = "ff_pins_reset_low", "ff_pins_reset_high", "ff_pins_irq_as_int","ff_pins_cs_mode",
                    "ff_pins_spi_clk", "ff_pins_spi_mosi", "ff_pins_spi_miso",
                    "ff_pins_spi_clk_low", "ff_pins_spi_mosi_low", "ff_pins_spi_miso_low", "ff_pins_spi_cs_low";
	pinctrl-0 = <&ff_pins_reset_low>;
	pinctrl-1 = <&ff_pins_reset_high>;
	pinctrl-2 = <&ff_pins_irq_as_int>;
	pinctrl-3 = <&ff_pins_cs_mode>;
	pinctrl-4 = <&ff_pins_spi_clk>;
	pinctrl-5 = <&ff_pins_spi_mosi>;
	pinctrl-6 = <&ff_pins_spi_miso>;
	pinctrl-7 = <&ff_pins_spi_clk_low>;
	pinctrl-8 = <&ff_pins_spi_mosi_low>;
	pinctrl-9 = <&ff_pins_spi_miso_low>;
	pinctrl-10 = <&ff_pins_spi_cs_low>;
	status = "okay";
};
&pio{
ff_pins_reset_low: ff_pins_reset_low {
				pins_cmd_dat {
					pinmux = <PINMUX_GPIO21__FUNC_GPIO21>;
					slew-rate = <1>;
					output-low;
				};
			};
ff_pins_reset_high: ff_pins_reset_high {
				pins_cmd_dat {
					pinmux = <PINMUX_GPIO21__FUNC_GPIO21>;
					slew-rate = <1>;
					output-high;
				};
			};
ff_pins_irq_as_int: ff_pins_irq_as_int {
				pins_cmd_dat {
					pinmux = <PINMUX_GPIO22__FUNC_GPIO22>;
					slew-rate = <1>;
					output-high;
				};
			};
	ff_pins_cs_mode: ff_pins_cs_mode {
		pins_cmd_dat {
			pinmux = <PINMUX_GPIO36__FUNC_SPI5_CSB>;
			drive-strength = <2>;
		};
	};
	ff_pins_spi_clk: ff_pins_spi_clk {
		pins_cmd_dat {
			pinmux = <PINMUX_GPIO35__FUNC_SPI5_CLK>;
			drive-strength = <2>;
		};
	};
	ff_pins_spi_mosi: ff_pins_spi_mosi {
		pins_cmd_dat {
			pinmux = <PINMUX_GPIO37__FUNC_SPI5_MO>;
			drive-strength = <2>;
		};
	};
	ff_pins_spi_miso: ff_pins_spi_miso {
		pins_cmd_dat {
			pinmux = <PINMUX_GPIO38__FUNC_SPI5_MI>;
			drive-strength = <3>;
		};
	};
	ff_pins_spi_clk_low: ff_pins_spi_clk_low {
		pins_cmd_dat {
			pinmux = <PINMUX_GPIO35__FUNC_GPIO35>;
			slew-rate = <1>;
			output-low;
		};
	};
	ff_pins_spi_mosi_low: ff_pins_spi_mosi_low {
		pins_cmd_dat {
			pinmux = <PINMUX_GPIO37__FUNC_GPIO37>;
			slew-rate = <1>;
			output-low;
		};
	};
	ff_pins_spi_miso_low: ff_pins_spi_miso_low {
		pins_cmd_dat {
			pinmux = <PINMUX_GPIO38__FUNC_SPI5_MI>;
			slew-rate = <1>;
			output-low;
		};
	};
	ff_pins_spi_cs_low: ff_pins_spi_cs_low {
		pins_cmd_dat {
			pinmux = <PINMUX_GPIO36__FUNC_GPIO36>;
			slew-rate = <1>;
			output-low;
		};
	};
};

&pio{
	gpio_id0_default: gpio_id0_default {
		pins_cmd_dat {
			pinmux = <PINMUX_GPIO140__FUNC_GPIO140>;
			slew-rate = <0>;
			bias-pull-up = <00>;
			input-enable;
		};
	};
};


&spi5 {
	#address-cells = <1>;
	#size-cells = <0>;
	status = "okay";
	oplus_fp: fingerprint@0 {
                 compatible = "mediatek,fingerspi-fp";
                 reg = <0>;
                 spi-max-frequency = <8000000>;
                 spi-id = <5>;
                 spi-irq = <39>;
                 spi-reg = <11019000>;
                 vmch-supply = <&mt_pmic_vfp_ldo_reg>;
                 vmch-config = <3000000 3000000 150000>;
                 power-num = <1>;
                 status = "okay";
                 power_source_1 {
                         power-mode = <1>;
                         power-name = "vmch";
                         power-config = "vmch-config";
                         delay-time = <0>;
                 };
         };
};
/* FINGERPRINT end */
//#endif /*OPLUS_FEATURE_FINGERPRINT*/
/* GPS GPIO standardization end */
#include "mediatek/cust_mt6833_camera_22669.dtsi"
#include <oplus6833_2260B/cust.dtsi>

//#ifdef OPLUS_FEATURE_CHG_BASIC
#include "mediatek/oplus_charge_mt6833_2260B.dtsi"
//#endif
&mmc1 {
    cd-gpios = <&pio 4 0>;
    status = "okay";
    vmmc-supply = <&mt_pmic_vmch_ldo_reg>;
};
&mt6360_ldo {
	sdcard_det_en = <1>;
	sdcard_hlact = <0>;
};
/*End of this file, DO NOT ADD ANYTHING HERE*/
